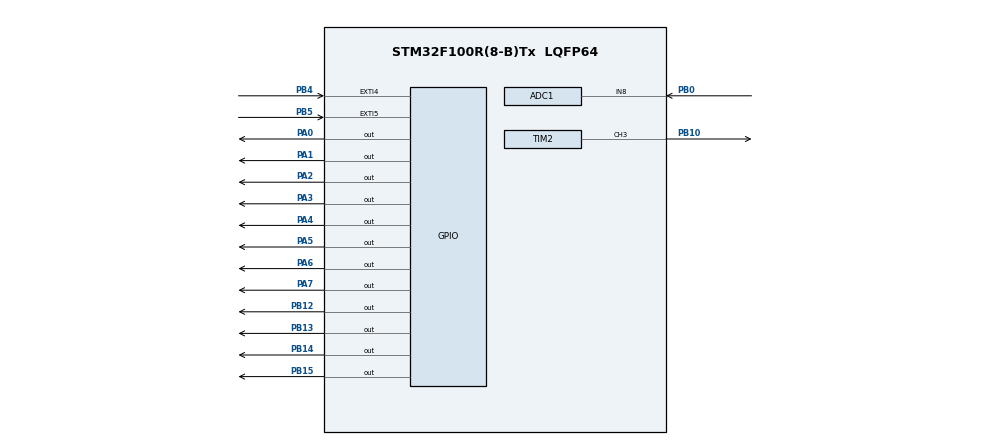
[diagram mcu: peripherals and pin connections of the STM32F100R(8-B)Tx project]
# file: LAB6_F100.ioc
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ADC1.Channel-5\#ChannelRegularConversion=ADC_CHANNEL_8
ADC1.ContinuousConvMode=ENABLE
ADC1.NbrOfConversionFlag=1
ADC1.Rank-5\#ChannelRegularConversion=1
ADC1.SamplingTime-5\#ChannelRegularConversion=ADC_SAMPLETIME_1CYCLE_5
ADC1.master=1
Mcu.Family=STM32F1
Mcu.Name=STM32F100R(8-B)Tx
Mcu.Package=LQFP64
NVIC.ADC1_IRQn=true\:0\:0\:false\:false\:true\:true\:true
NVIC.EXTI4_IRQn=true\:0\:0\:false\:false\:true\:true\:true
NVIC.EXTI9_5_IRQn=true\:0\:0\:false\:false\:true\:true\:true
NVIC.PriorityGroup=NVIC_PRIORITYGROUP_4
NVIC.TIM2_IRQn=true\:0\:0\:false\:false\:true\:true\:true
NVIC.TIM7_IRQn=true\:0\:0\:false\:false\:true\:true\:true
PA0-WKUP.Signal=GPIO_Output
PA1.Signal=GPIO_Output
PA13.Mode=Serial_Wire
PA13.Signal=SYS_JTMS-SWDIO
PA14.Mode=Serial_Wire
PA14.Signal=SYS_JTCK-SWCLK
PA2.Signal=GPIO_Output
PA3.Signal=GPIO_Output
PA4.Signal=GPIO_Output
PA5.Signal=GPIO_Output
PA6.Signal=GPIO_Output
PA7.Signal=GPIO_Output
PB0.Signal=ADCx_IN8
PB10.Signal=S_TIM2_CH3
PB12.Signal=GPIO_Output
PB13.Signal=GPIO_Output
PB14.Signal=GPIO_Output
PB15.Signal=GPIO_Output
PB4.GPIO_ModeDefaultEXTI=GPIO_MODE_IT_FALLING
PB4.GPIO_PuPd=GPIO_PULLUP
PB4.Signal=GPXTI4
PB5.GPIO_ModeDefaultEXTI=GPIO_MODE_IT_FALLING
PB5.GPIO_PuPd=GPIO_PULLUP
PB5.Signal=GPXTI5
PD0-OSC_IN.Mode=HSE-External-Oscillator
PD0-OSC_IN.Signal=RCC_OSC_IN
PD1-OSC_OUT.Mode=HSE-External-Oscillator
PD1-OSC_OUT.Signal=RCC_OSC_OUT
ProjectManager.HeapSize=0x200
ProjectManager.StackSize=0x400
ProjectManager.TargetToolchain=EWARM V8
RCC.APB1Freq_Value=8000000
RCC.APB2Freq_Value=8000000
SH.ADCx_IN8.0=ADC1_IN8,IN8
SH.S_TIM2_CH3.0=TIM2_CH3,PWM Generation3 CH3
TIM2.Channel-PWM\ Generation3\ CH3=TIM_CHANNEL_3
TIM2.Period=3200
TIM2.Prescaler=0
TIM7.Period=200
TIM7.Prescaler=199
VP_TIM2_VS_ClockSourceINT.Mode=Internal
VP_TIM7_VS_ClockSourceINT.Mode=Enable_Timer
board=custom

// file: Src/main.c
/* USER CODE BEGIN Header */
/**
  ******************************************************************************
  * @file           : main.c
  * @brief          : Main program body
  ******************************************************************************
  * @attention
  *
  * <h2><center>&copy; Copyright (c) 2019 STMicroelectronics.
  * All rights reserved.</center></h2>
  *
  * This software component is licensed by ST under BSD 3-Clause license,
  * the "License"; You may not use this file except in compliance with the
  * License. You may obtain a copy of the License at:
  *                        opensource.org/licenses/BSD-3-Clause
  *
  ******************************************************************************
  */
/* USER CODE END Header */

#include "main.h"

/* USER CODE BEGIN Includes */
#include "global.h"
/* USER CODE END Includes */

void SystemClock_Config(void);
static void MX_GPIO_Init(void);
static void MX_ADC1_Init(void);
static void MX_TIM2_Init(void);
static void MX_TIM7_Init(void);

int main(void)
{

  /* MCU Configuration--------------------------------------------------------*/

  /* Reset of all peripherals, Initializes the Flash interface and the Systick. */
  HAL_Init();

  /* Configure the system clock */
  SystemClock_Config();

  /* USER CODE BEGIN SysInit */
  LL_ADC_StartCalibration(ADC1);//?????? ?????????? ???1
  while (LL_ADC_IsCalibrationOnGoing(ADC1) != RESET);//??????? ?????????? ?????????? ???1

  /* USER CODE END SysInit */

  /* Initialize all configured peripherals */
  MX_GPIO_Init();
  MX_ADC1_Init();
  MX_TIM2_Init();
  MX_TIM7_Init();
  /* USER CODE BEGIN 2 */

  LL_ADC_EnableIT_EOS(ADC1);//?????????? ?????????? ?? ?????????? ?????????????? ? ???
  LL_ADC_Enable(ADC1);//????????? ???

  LL_TIM_EnableIT_UPDATE(TIM7);
  LL_TIM_EnableCounter(TIM7);

  LL_TIM_CC_EnableChannel(TIM2,LL_TIM_CHANNEL_CH3);

  LL_TIM_EnableIT_UPDATE(TIM2);
  LL_TIM_EnableCounter(TIM2);

  /* USER CODE END 2 */

  /* Infinite loop */
  while (1)
  {

  }
}

void SystemClock_Config(void)
{
  LL_RCC_HSI_SetCalibTrimming(16);
  LL_RCC_HSI_Enable();

   /* Wait till HSI is ready */
  while(LL_RCC_HSI_IsReady() != 1)
  {

  }
  LL_RCC_SetAHBPrescaler(LL_RCC_SYSCLK_DIV_1);
  LL_RCC_SetAPB1Prescaler(LL_RCC_APB1_DIV_1);
  LL_RCC_SetAPB2Prescaler(LL_RCC_APB2_DIV_1);
  LL_RCC_SetSysClkSource(LL_RCC_SYS_CLKSOURCE_HSI);

   /* Wait till System clock is ready */
  while(LL_RCC_GetSysClkSource() != LL_RCC_SYS_CLKSOURCE_STATUS_HSI)
  {

  }
  LL_Init1msTick(8000000);
  LL_SYSTICK_SetClkSource(LL_SYSTICK_CLKSOURCE_HCLK);
  LL_SetSystemCoreClock(8000000);
  LL_RCC_SetADCClockSource(LL_RCC_ADC_CLKSRC_PCLK2_DIV_2);
}

static void MX_ADC1_Init(void)
{

  LL_ADC_InitTypeDef ADC_InitStruct = {0};
  LL_ADC_REG_InitTypeDef ADC_REG_InitStruct = {0};

  LL_GPIO_InitTypeDef GPIO_InitStruct = {0};

  /* Peripheral clock enable */
  LL_APB2_GRP1_EnableClock(LL_APB2_GRP1_PERIPH_ADC1);

  LL_APB2_GRP1_EnableClock(LL_APB2_GRP1_PERIPH_GPIOB);
  /**ADC1 GPIO Configuration
  PB0   ------> ADC1_IN8
  */
  GPIO_InitStruct.Pin = LL_GPIO_PIN_0;
  GPIO_InitStruct.Mode = LL_GPIO_MODE_ANALOG;
  LL_GPIO_Init(GPIOB, &GPIO_InitStruct);

  /* ADC1 interrupt Init */
  NVIC_SetPriority(ADC1_IRQn, NVIC_EncodePriority(NVIC_GetPriorityGrouping(),0, 0));
  NVIC_EnableIRQ(ADC1_IRQn);

  /** Common config
  */
  ADC_InitStruct.DataAlignment = LL_ADC_DATA_ALIGN_RIGHT;
  ADC_InitStruct.SequencersScanMode = LL_ADC_SEQ_SCAN_DISABLE;
  LL_ADC_Init(ADC1, &ADC_InitStruct);
  ADC_REG_InitStruct.TriggerSource = LL_ADC_REG_TRIG_SOFTWARE;
  ADC_REG_InitStruct.SequencerLength = 1;
  ADC_REG_InitStruct.SequencerDiscont = LL_ADC_REG_SEQ_DISCONT_DISABLE;
  ADC_REG_InitStruct.ContinuousMode = LL_ADC_REG_CONV_CONTINUOUS;
  ADC_REG_InitStruct.DMATransfer = LL_ADC_REG_DMA_TRANSFER_NONE;
  LL_ADC_REG_Init(ADC1, &ADC_REG_InitStruct);
  /** Configure Regular Channel
  */
  LL_ADC_REG_SetSequencerRanks(ADC1, LL_ADC_REG_RANK_1, LL_ADC_CHANNEL_8);
  LL_ADC_SetChannelSamplingTime(ADC1, LL_ADC_CHANNEL_8, LL_ADC_SAMPLINGTIME_1CYCLE_5);

}

static void MX_TIM2_Init(void)
{

  LL_TIM_InitTypeDef TIM_InitStruct = {0};
  LL_TIM_OC_InitTypeDef TIM_OC_InitStruct = {0};

  LL_GPIO_InitTypeDef GPIO_InitStruct = {0};

  /* Peripheral clock enable */
  LL_APB1_GRP1_EnableClock(LL_APB1_GRP1_PERIPH_TIM2);

  /* TIM2 interrupt Init */
  NVIC_SetPriority(TIM2_IRQn, NVIC_EncodePriority(NVIC_GetPriorityGrouping(),0, 0));
  NVIC_EnableIRQ(TIM2_IRQn);

  TIM_InitStruct.Prescaler = 0;
  TIM_InitStruct.CounterMode = LL_TIM_COUNTERMODE_UP;
  TIM_InitStruct.Autoreload = 3200;
  TIM_InitStruct.ClockDivision = LL_TIM_CLOCKDIVISION_DIV1;
  LL_TIM_Init(TIM2, &TIM_InitStruct);
  LL_TIM_DisableARRPreload(TIM2);
  LL_TIM_SetClockSource(TIM2, LL_TIM_CLOCKSOURCE_INTERNAL);
  LL_TIM_OC_EnablePreload(TIM2, LL_TIM_CHANNEL_CH3);
  TIM_OC_InitStruct.OCMode = LL_TIM_OCMODE_PWM1;
  TIM_OC_InitStruct.OCState = LL_TIM_OCSTATE_DISABLE;
  TIM_OC_InitStruct.OCNState = LL_TIM_OCSTATE_DISABLE;
  TIM_OC_InitStruct.CompareValue = 0;
  TIM_OC_InitStruct.OCPolarity = LL_TIM_OCPOLARITY_HIGH;
  LL_TIM_OC_Init(TIM2, LL_TIM_CHANNEL_CH3, &TIM_OC_InitStruct);
  LL_TIM_OC_DisableFast(TIM2, LL_TIM_CHANNEL_CH3);
  LL_TIM_SetTriggerOutput(TIM2, LL_TIM_TRGO_RESET);
  LL_TIM_DisableMasterSlaveMode(TIM2);
  LL_APB2_GRP1_EnableClock(LL_APB2_GRP1_PERIPH_GPIOB);
  /**TIM2 GPIO Configuration
  PB10   ------> TIM2_CH3
  */
  GPIO_InitStruct.Pin = LL_GPIO_PIN_10;
  GPIO_InitStruct.Mode = LL_GPIO_MODE_ALTERNATE;
  GPIO_InitStruct.Speed = LL_GPIO_SPEED_FREQ_LOW;
  GPIO_InitStruct.OutputType = LL_GPIO_OUTPUT_PUSHPULL;
  LL_GPIO_Init(GPIOB, &GPIO_InitStruct);

  LL_GPIO_AF_RemapPartial2_TIM2();

}

static void MX_TIM7_Init(void)
{

  LL_TIM_InitTypeDef TIM_InitStruct = {0};

  /* Peripheral clock enable */
  LL_APB1_GRP1_EnableClock(LL_APB1_GRP1_PERIPH_TIM7);

  /* TIM7 interrupt Init */
  NVIC_SetPriority(TIM7_IRQn, NVIC_EncodePriority(NVIC_GetPriorityGrouping(),0, 0));
  NVIC_EnableIRQ(TIM7_IRQn);

  TIM_InitStruct.Prescaler = 199;
  TIM_InitStruct.CounterMode = LL_TIM_COUNTERMODE_UP;
  TIM_InitStruct.Autoreload = 200;
  LL_TIM_Init(TIM7, &TIM_InitStruct);
  LL_TIM_DisableARRPreload(TIM7);
  LL_TIM_SetTriggerOutput(TIM7, LL_TIM_TRGO_RESET);
  LL_TIM_DisableMasterSlaveMode(TIM7);

}

static void MX_GPIO_Init(void)
{
  GPIO_InitTypeDef GPIO_InitStruct = {0};

  /* GPIO Ports Clock Enable */
  __HAL_RCC_GPIOD_CLK_ENABLE();
  __HAL_RCC_GPIOA_CLK_ENABLE();
  __HAL_RCC_GPIOB_CLK_ENABLE();

  /*Configure GPIO pin Output Level */
  HAL_GPIO_WritePin(GPIOA, GPIO_PIN_0|GPIO_PIN_1|GPIO_PIN_2|GPIO_PIN_3
                          |GPIO_PIN_4|GPIO_PIN_5|GPIO_PIN_6|GPIO_PIN_7, GPIO_PIN_RESET);

  /*Configure GPIO pin Output Level */
  HAL_GPIO_WritePin(GPIOB, GPIO_PIN_12|GPIO_PIN_13|GPIO_PIN_14|GPIO_PIN_15, GPIO_PIN_RESET);

  /*Configure GPIO pins : PA0 PA1 PA2 PA3
                           PA4 PA5 PA6 PA7 */
  GPIO_InitStruct.Pin = GPIO_PIN_0|GPIO_PIN_1|GPIO_PIN_2|GPIO_PIN_3
                          |GPIO_PIN_4|GPIO_PIN_5|GPIO_PIN_6|GPIO_PIN_7;
  GPIO_InitStruct.Mode = GPIO_MODE_OUTPUT_PP;
  GPIO_InitStruct.Pull = GPIO_NOPULL;
  GPIO_InitStruct.Speed = GPIO_SPEED_FREQ_LOW;
  HAL_GPIO_Init(GPIOA, &GPIO_InitStruct);

  /*Configure GPIO pins : PB12 PB13 PB14 PB15 */
  GPIO_InitStruct.Pin = GPIO_PIN_12|GPIO_PIN_13|GPIO_PIN_14|GPIO_PIN_15;
  GPIO_InitStruct.Mode = GPIO_MODE_OUTPUT_PP;
  GPIO_InitStruct.Pull = GPIO_NOPULL;
  GPIO_InitStruct.Speed = GPIO_SPEED_FREQ_LOW;
  HAL_GPIO_Init(GPIOB, &GPIO_InitStruct);

  /*Configure GPIO pins : PB4 PB5 */
  GPIO_InitStruct.Pin = GPIO_PIN_4|GPIO_PIN_5;
  GPIO_InitStruct.Mode = GPIO_MODE_IT_FALLING;
  GPIO_InitStruct.Pull = GPIO_PULLUP;
  HAL_GPIO_Init(GPIOB, &GPIO_InitStruct);

  /* EXTI interrupt init*/
  HAL_NVIC_SetPriority(EXTI4_IRQn, 0, 0);
  HAL_NVIC_EnableIRQ(EXTI4_IRQn);

  HAL_NVIC_SetPriority(EXTI9_5_IRQn, 0, 0);
  HAL_NVIC_EnableIRQ(EXTI9_5_IRQn);

}

void Error_Handler(void)
{
}

/************************ (C) COPYRIGHT STMicroelectronics *****END OF FILE****/
